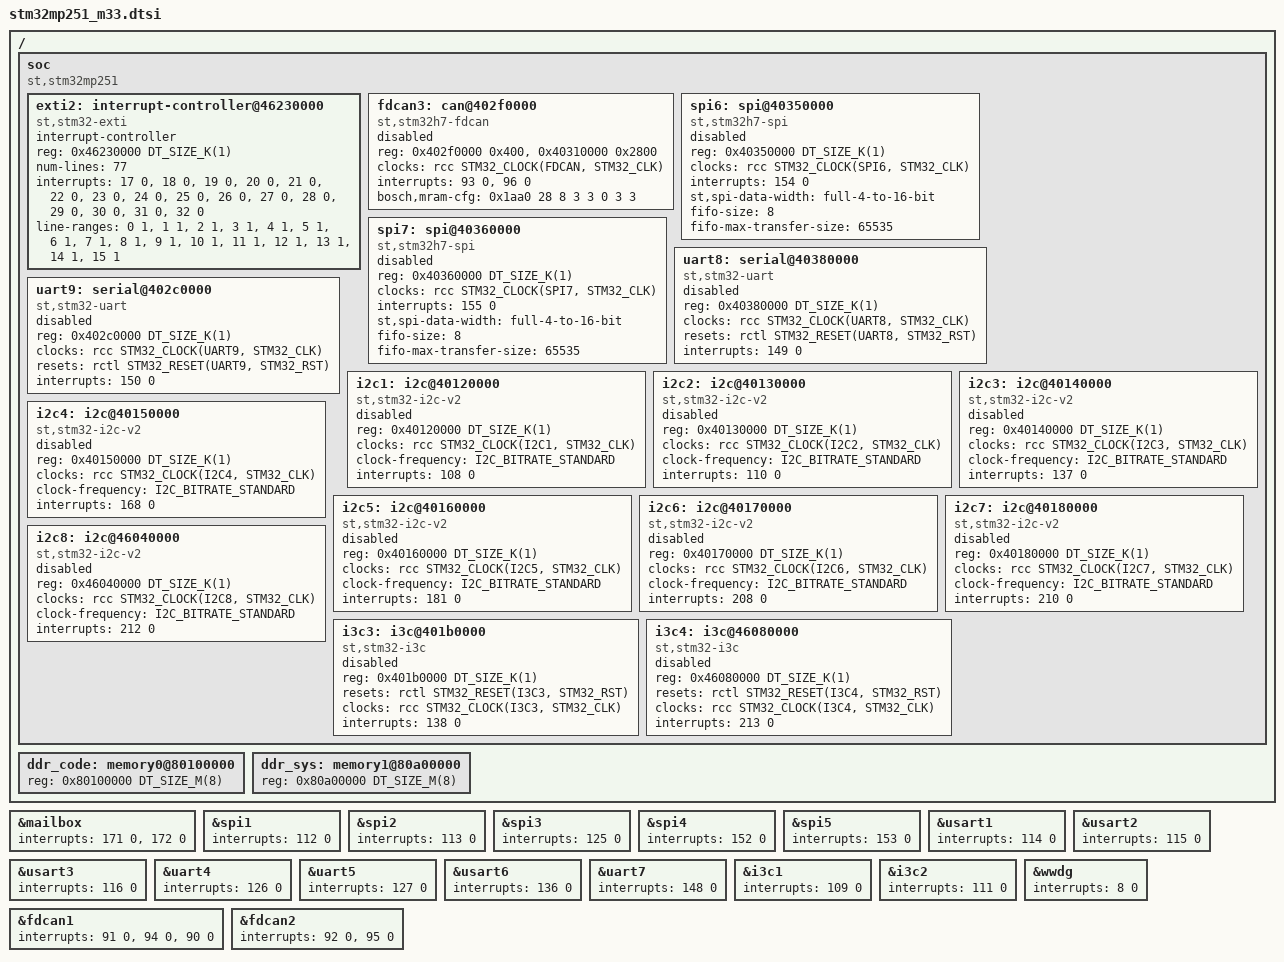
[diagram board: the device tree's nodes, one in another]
/*
 * Copyright (C) 2025 Savoir-faire Linux, Inc.
 *
 * SPDX-License-Identifier: Apache-2.0
 */

#include <st/mp2/stm32mp2_m33.dtsi>

/ {
	soc {
		compatible = "st,stm32mp251", "st,stm32mp2", "simple-bus";

		exti2: interrupt-controller@46230000 {
			compatible = "st,stm32-exti";
			interrupt-controller;
			#interrupt-cells = <1>;
			#address-cells = <0>;
			reg = <0x46230000 DT_SIZE_K(1)>;
			num-lines = <77>;
			interrupts = <17 0>, <18 0>, <19 0>, <20 0>,
				     <21 0>, <22 0>, <23 0>, <24 0>,
				     <25 0>, <26 0>, <27 0>, <28 0>,
				     <29 0>, <30 0>, <31 0>, <32 0>;
			interrupt-names = "line0", "line1", "line2", "line3",
					  "line4", "line5", "line6", "line7",
					  "line8", "line9", "line10", "line11",
					  "line12", "line13", "line14", "line15";
			line-ranges = <0 1>, <1 1>, <2 1>, <3 1>,
				      <4 1>, <5 1>, <6 1>, <7 1>,
				      <8 1>, <9 1>, <10 1>, <11 1>,
				      <12 1>, <13 1>, <14 1>, <15 1>;
		};

		fdcan3: can@402f0000 {
			compatible = "st,stm32h7-fdcan";
			reg = <0x402f0000 0x400>, <0x40310000 0x2800>;
			reg-names = "m_can", "message_ram";
			clocks = <&rcc STM32_CLOCK(FDCAN, STM32_CLK)>;
			interrupts = <93 0>, <96 0>;
			interrupt-names = "int0", "int1";
			bosch,mram-cfg = <0x1aa0 28 8 3 3 0 3 3>;
			status = "disabled";
		};

		spi6: spi@40350000 {
			compatible = "st,stm32h7-spi", "st,stm32-spi-fifo", "st,stm32-spi";
			reg = <0x40350000 DT_SIZE_K(1)>;
			#address-cells = <1>;
			#size-cells = <0>;
			clocks = <&rcc STM32_CLOCK(SPI6, STM32_CLK)>;
			interrupts = <154 0>;
			st,spi-data-width = "full-4-to-16-bit";
			fifo-size = <8>;
			fifo-max-transfer-size = <65535>;
			status = "disabled";
		};

		spi7: spi@40360000 {
			compatible = "st,stm32h7-spi", "st,stm32-spi-fifo", "st,stm32-spi";
			reg = <0x40360000 DT_SIZE_K(1)>;
			#address-cells = <1>;
			#size-cells = <0>;
			clocks = <&rcc STM32_CLOCK(SPI7, STM32_CLK)>;
			interrupts = <155 0>;
			st,spi-data-width = "full-4-to-16-bit";
			fifo-size = <8>;
			fifo-max-transfer-size = <65535>;
			status = "disabled";
		};

		uart8: serial@40380000 {
			compatible = "st,stm32-uart";
			reg = <0x40380000 DT_SIZE_K(1)>;
			clocks = <&rcc STM32_CLOCK(UART8, STM32_CLK)>;
			resets = <&rctl STM32_RESET(UART8, STM32_RST)>;
			interrupts = <149 0>;
			status = "disabled";
		};

		uart9: serial@402c0000 {
			compatible = "st,stm32-uart";
			reg = <0x402c0000 DT_SIZE_K(1)>;
			clocks = <&rcc STM32_CLOCK(UART9, STM32_CLK)>;
			resets = <&rctl STM32_RESET(UART9, STM32_RST)>;
			interrupts = <150 0>;
			status = "disabled";
		};

		i2c1: i2c@40120000 {
			compatible = "st,stm32-i2c-v2";
			reg = <0x40120000 DT_SIZE_K(1)>;
			#address-cells = <1>;
			#size-cells = <0>;
			clocks = <&rcc STM32_CLOCK(I2C1, STM32_CLK)>;
			clock-frequency = <I2C_BITRATE_STANDARD>;
			interrupts = <108 0>;
			interrupt-names = "combined";
			status = "disabled";
		};

		i2c2: i2c@40130000 {
			compatible = "st,stm32-i2c-v2";
			reg = <0x40130000 DT_SIZE_K(1)>;
			#address-cells = <1>;
			#size-cells = <0>;
			clocks = <&rcc STM32_CLOCK(I2C2, STM32_CLK)>;
			clock-frequency = <I2C_BITRATE_STANDARD>;
			interrupts = <110 0>;
			interrupt-names = "combined";
			status = "disabled";
		};

		i2c3: i2c@40140000 {
			compatible = "st,stm32-i2c-v2";
			reg = <0x40140000 DT_SIZE_K(1)>;
			#address-cells = <1>;
			#size-cells = <0>;
			clocks = <&rcc STM32_CLOCK(I2C3, STM32_CLK)>;
			clock-frequency = <I2C_BITRATE_STANDARD>;
			interrupts = <137 0>;
			interrupt-names = "combined";
			status = "disabled";
		};

		i2c4: i2c@40150000 {
			compatible = "st,stm32-i2c-v2";
			reg = <0x40150000 DT_SIZE_K(1)>;
			#address-cells = <1>;
			#size-cells = <0>;
			clocks = <&rcc STM32_CLOCK(I2C4, STM32_CLK)>;
			clock-frequency = <I2C_BITRATE_STANDARD>;
			interrupts = <168 0>;
			interrupt-names = "combined";
			status = "disabled";
		};

		i2c5: i2c@40160000 {
			compatible = "st,stm32-i2c-v2";
			reg = <0x40160000 DT_SIZE_K(1)>;
			#address-cells = <1>;
			#size-cells = <0>;
			clocks = <&rcc STM32_CLOCK(I2C5, STM32_CLK)>;
			clock-frequency = <I2C_BITRATE_STANDARD>;
			interrupts = <181 0>;
			interrupt-names = "combined";
			status = "disabled";
		};

		i2c6: i2c@40170000 {
			compatible = "st,stm32-i2c-v2";
			reg = <0x40170000 DT_SIZE_K(1)>;
			#address-cells = <1>;
			#size-cells = <0>;
			clocks = <&rcc STM32_CLOCK(I2C6, STM32_CLK)>;
			clock-frequency = <I2C_BITRATE_STANDARD>;
			interrupts = <208 0>;
			interrupt-names = "combined";
			status = "disabled";
		};

		i2c7: i2c@40180000 {
			compatible = "st,stm32-i2c-v2";
			reg = <0x40180000 DT_SIZE_K(1)>;
			#address-cells = <1>;
			#size-cells = <0>;
			clocks = <&rcc STM32_CLOCK(I2C7, STM32_CLK)>;
			clock-frequency = <I2C_BITRATE_STANDARD>;
			interrupts = <210 0>;
			interrupt-names = "combined";
			status = "disabled";
		};

		i2c8: i2c@46040000 {
			compatible = "st,stm32-i2c-v2";
			reg = <0x46040000 DT_SIZE_K(1)>;
			#address-cells = <1>;
			#size-cells = <0>;
			clocks = <&rcc STM32_CLOCK(I2C8, STM32_CLK)>;
			clock-frequency = <I2C_BITRATE_STANDARD>;
			interrupts = <212 0>;
			interrupt-names = "combined";
			status = "disabled";
		};

		i3c3: i3c@401b0000 {
			compatible = "st,stm32-i3c";
			reg = <0x401b0000 DT_SIZE_K(1)>;
			#address-cells = <3>;
			#size-cells = <0>;
			resets = <&rctl STM32_RESET(I3C3, STM32_RST)>;
			clocks = <&rcc STM32_CLOCK(I3C3, STM32_CLK)>;
			interrupts = <138 0>;
			interrupt-names = "combined";
			status = "disabled";
		};

		i3c4: i3c@46080000 {
			compatible = "st,stm32-i3c";
			reg = <0x46080000 DT_SIZE_K(1)>;
			#address-cells = <3>;
			#size-cells = <0>;
			resets = <&rctl STM32_RESET(I3C4, STM32_RST)>;
			clocks = <&rcc STM32_CLOCK(I3C4, STM32_CLK)>;
			interrupts = <213 0>;
			interrupt-names = "combined";
			status = "disabled";
		};
	};

	ddr_code: memory0@80100000 {
		reg = <0x80100000 DT_SIZE_M(8)>;
		ranges = <0x0 0x80100000 DT_SIZE_M(8)>;
		#address-cells = <1>;
		#size-cells = <1>;
	};

	ddr_sys: memory1@80a00000 {
		reg = <0x80a00000 DT_SIZE_M(8)>;
		ranges = <0x0 0x80a00000 DT_SIZE_M(8)>;
		#address-cells = <1>;
		#size-cells = <1>;
	};
};

&mailbox {
	interrupts = <171 0>, <172 0>;
	interrupt-names = "rxo", "txf";
};

&spi1 {
	interrupts = <112 0>;
};

&spi2 {
	interrupts = <113 0>;
};

&spi3 {
	interrupts = <125 0>;
};

&spi4 {
	interrupts = <152 0>;
};

&spi5 {
	interrupts = <153 0>;
};

&usart1 {
	interrupts = <114 0>;
};

&usart2 {
	interrupts = <115 0>;
};

&usart3 {
	interrupts = <116 0>;
};

&uart4 {
	interrupts = <126 0>;
};

&uart5 {
	interrupts = <127 0>;
};

&usart6 {
	interrupts = <136 0>;
};

&uart7 {
	interrupts = <148 0>;
};

&i3c1 {
	interrupts = <109 0>;
};

&i3c2 {
	interrupts = <111 0>;
};

&wwdg {
	interrupts = <8 0>;
};

&fdcan1 {
	interrupts = <91 0>, <94 0>, <90 0>;
	interrupt-names = "int0", "int1", "calib";
};

&fdcan2 {
	interrupts = <92 0>, <95 0>;
	interrupt-names = "int0", "int1";
};
